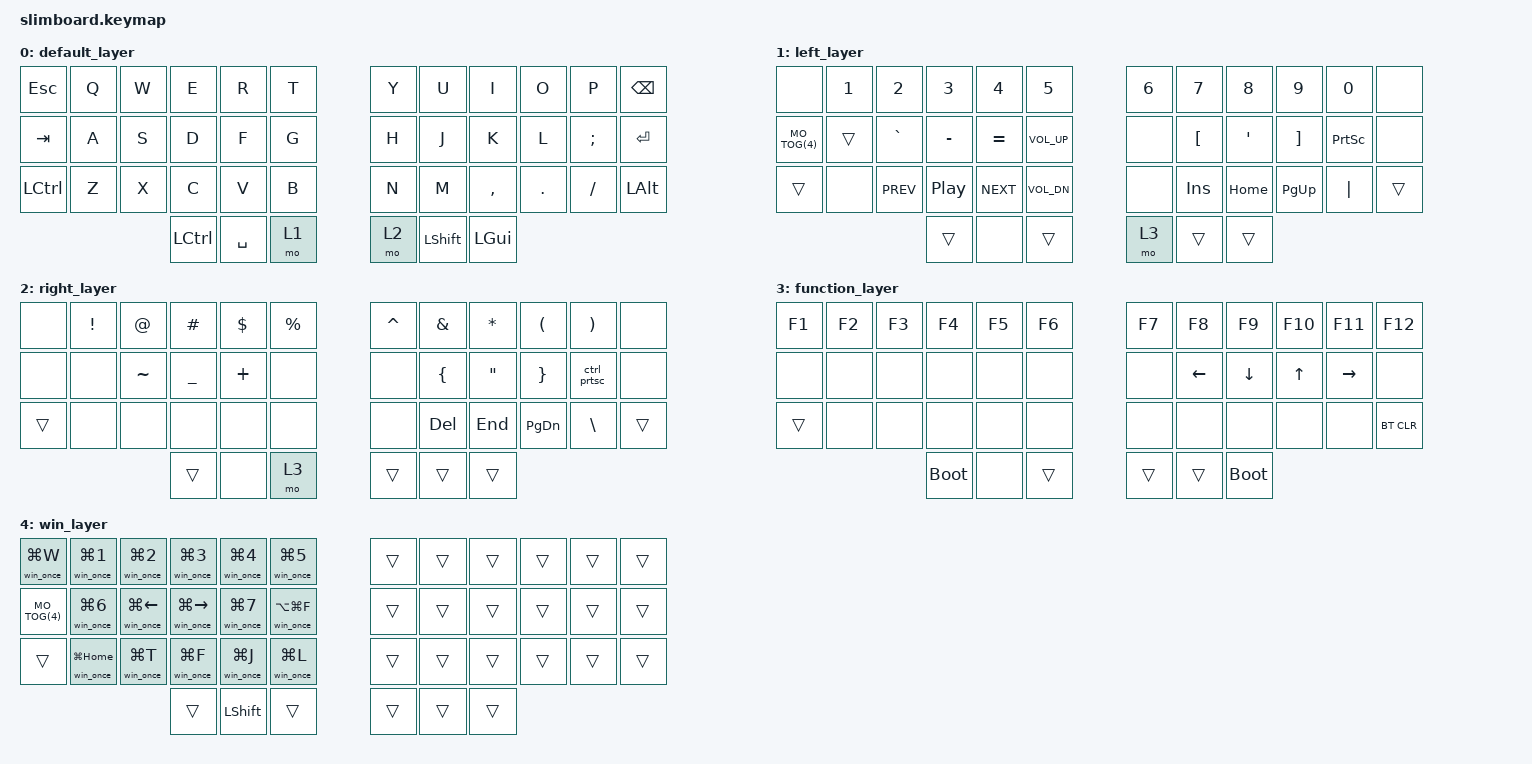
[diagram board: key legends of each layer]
#include <behaviors.dtsi>
#include <dt-bindings/zmk/keys.h>
#include <dt-bindings/zmk/bt.h>

#define MO_TOG(layer) &mo_tog layer layer

/ {
        behaviors {
                mo_tog: behavior_mo_tog {
                        compatible = "zmk,behavior-hold-tap";
                        #binding-cells = <2>;
                        flavor = "hold-preferred";
                        tapping-term-ms = <200>;
                        bindings = <&mo>, <&tog>;
                };
        };

        combos {
                compatible = "zmk,combos";
                
                combo_enter {
                        timeout-ms = <50>;
                        key-positions = <16 19>;
                        bindings = <&kp RET>;
                };
                
                combo_backspace {
                        timeout-ms = <50>;
                        key-positions = <15 20>;
                        bindings = <&kp BSPC>;
                };
                
                combo_q {
                        timeout-ms = <50>;
                        key-positions = <13 22>;
                        bindings = <&kp Q>;
                };
                
                combo_p {
                        timeout-ms = <50>;
                        key-positions = <14 21>;
                        bindings = <&kp P>;
                };
        };

        macros {
                ctrl_prtsc: ctrl_prtsc {
                        compatible = "zmk,behavior-macro";
                        #binding-cells = <0>;
                        bindings = <&kp LC(PSCRN)>;
                };

                win_once: win_once {
                        compatible = "zmk,behavior-macro-one-param";
                        #binding-cells = <1>;
                        bindings = <&macro_param_1to1>, <&kp MACRO_PLACEHOLDER>, <&to 0>;
                };
        };

        keymap {
                compatible = "zmk,keymap";

                default_layer {
                        bindings = <
   &kp ESC             &kp Q               &kp W               &kp E               &kp R               &kp T               &kp Y               &kp U               &kp I               &kp O               &kp P               &kp BSPC            
   &kp TAB             &kp A               &kp S               &kp D               &kp F               &kp G               &kp H               &kp J               &kp K               &kp L               &kp SEMI            &kp RET             
   &kp LCTRL           &kp Z               &kp X               &kp C               &kp V               &kp B               &kp N               &kp M               &kp COMMA           &kp DOT             &kp FSLH            &kp LALT            
                                                                                                                           &kp LCTRL           &kp SPACE           &mo 1               &mo 2               &kp LSHFT           &kp LGUI            
                        >;
                };

                left_layer {
                        bindings = <
   &none               &kp N1              &kp N2              &kp N3              &kp N4              &kp N5              &kp N6              &kp N7              &kp N8              &kp N9              &kp N0              &none               
   MO_TOG(4)           &trans              &kp GRAVE           &kp MINUS           &kp EQUAL           &kp C_VOL_UP        &none               &kp LBKT            &kp SQT             &kp RBKT            &kp PSCRN           &none
   &trans              &none               &kp C_PREV          &kp C_PP            &kp C_NEXT          &kp C_VOL_DN        &none               &kp INS             &kp HOME            &kp PG_UP           &kp PIPE            &trans              
                                                                                                                           &trans              &none               &trans              &mo 3               &trans              &trans              
                        >;
                };

                right_layer {
                        bindings = <
   &none               &kp EXCL            &kp AT              &kp HASH            &kp DLLR            &kp PRCNT           &kp CARET           &kp AMPS            &kp ASTRK           &kp LPAR            &kp RPAR            &none               
   &none               &none               &kp TILDE           &kp UNDER           &kp PLUS            &none               &none               &kp LBRC            &kp DQT             &kp RBRC            &ctrl_prtsc         &none               
   &trans              &none               &none               &none               &none               &none               &none               &kp DEL             &kp END             &kp PG_DN           &kp BSLH            &trans              
                                                                                                                           &trans              &none               &mo 3               &trans              &trans              &trans              
                        >;
                };

                function_layer {
                        bindings = <
   &kp F1              &kp F2              &kp F3              &kp F4              &kp F5              &kp F6              &kp F7              &kp F8              &kp F9              &kp F10             &kp F11             &kp F12             
   &none               &none               &none               &none               &none               &none               &none               &kp LEFT            &kp DOWN            &kp UP              &kp RIGHT           &none               
   &trans              &none               &none               &none               &none               &none               &none               &none               &none               &none               &none               &bt BT_CLR               
                                                                                                                           &bootloader         &none               &trans              &trans              &trans              &bootloader         
                        >;
                };

                win_layer {
                        bindings = <
   &win_once LG(W)     &win_once LG(N1)    &win_once LG(N2)    &win_once LG(N3)    &win_once LG(N4)    &win_once LG(N5)    &trans              &trans              &trans              &trans              &trans              &trans
   MO_TOG(4)           &win_once LG(N6)    &win_once LG(LEFT)  &win_once LG(RIGHT) &win_once LG(N7)    &win_once LA(LG(F)) &trans              &trans              &trans              &trans              &trans              &trans
   &trans              &win_once LG(HOME)  &win_once LG(T)     &win_once LG(F)     &win_once LG(J)     &win_once LG(L)     &trans              &trans              &trans              &trans              &trans              &trans
                                                                                                                           &trans              &kp LSHFT           &trans              &trans              &trans              &trans
                        >;
                };
        };
};
